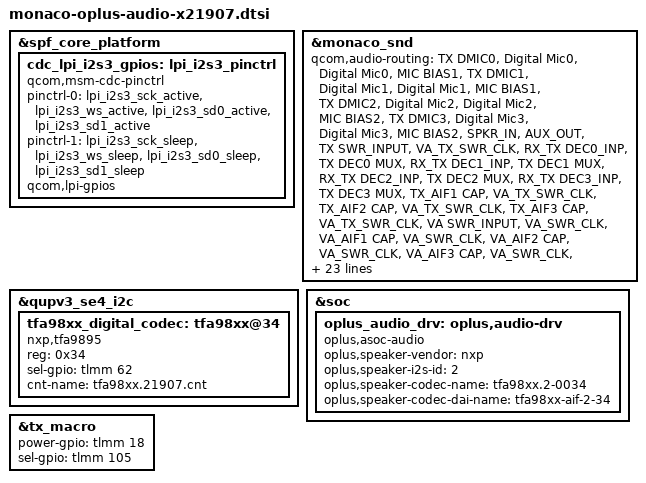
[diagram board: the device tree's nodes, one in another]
//From:

#include <dt-bindings/gpio/gpio.h>

&spf_core_platform {
    cdc_lpi_i2s3_gpios: lpi_i2s3_pinctrl {
        status= "ok";
        compatible = "qcom,msm-cdc-pinctrl";
        pinctrl-names = "aud_active", "aud_sleep";
        pinctrl-0 = <&lpi_i2s3_sck_active &lpi_i2s3_ws_active
                &lpi_i2s3_sd0_active &lpi_i2s3_sd1_active>;
        pinctrl-1 = <&lpi_i2s3_sck_sleep &lpi_i2s3_ws_sleep
                &lpi_i2s3_sd0_sleep &lpi_i2s3_sd1_sleep>;
        #gpio-cells = <0>;
        qcom,lpi-gpios;
    };
};

&monaco_snd {
    qcom,audio-routing =
            "TX DMIC0", "Digital Mic0",
            "Digital Mic0", "MIC BIAS1",
            "TX DMIC1", "Digital Mic1",
            "Digital Mic1", "MIC BIAS1",
            "TX DMIC2", "Digital Mic2",
            "Digital Mic2", "MIC BIAS2",
            "TX DMIC3", "Digital Mic3",
            "Digital Mic3", "MIC BIAS2",
            "SPKR_IN", "AUX_OUT",
            "TX SWR_INPUT", "VA_TX_SWR_CLK",
            "RX_TX DEC0_INP", "TX DEC0 MUX",
            "RX_TX DEC1_INP", "TX DEC1 MUX",
            "RX_TX DEC2_INP", "TX DEC2 MUX",
            "RX_TX DEC3_INP", "TX DEC3 MUX",
            "TX_AIF1 CAP", "VA_TX_SWR_CLK",
            "TX_AIF2 CAP", "VA_TX_SWR_CLK",
            "TX_AIF3 CAP", "VA_TX_SWR_CLK",
            "VA SWR_INPUT", "VA_SWR_CLK",
            "VA_AIF1 CAP", "VA_SWR_CLK",
            "VA_AIF2 CAP", "VA_SWR_CLK",
            "VA_AIF3 CAP", "VA_SWR_CLK",
            "VA DMIC0", "Digital Mic0",
            "VA DMIC1", "Digital Mic1",
            "VA DMIC2", "Digital Mic2",
            "VA DMIC3", "Digital Mic3",
            "VA DMIC0", "VA MIC BIAS1",
            "VA DMIC1", "VA MIC BIAS1",
            "VA DMIC2", "VA MIC BIAS2",
            "VA DMIC3", "VA MIC BIAS2",
            "AMIC1", "Analog Mic1",
            "Analog Mic1","MIC BIAS1",
            "AMIC2", "Analog Mic2",
            "Analog Mic2", "MIC BIAS2",
            "SPKR_IN", "AUX_OUT",
            "TX SWR_INPUT", "VA_TX_SWR_CLK",
            "RX_SWR_TX_PCM_IN0", "RX_MCLK",
            "RX_SWR_TX_PCM_IN1", "RX_MCLK",
            "RX_SWR_TX_PCM_IN0", "ADC1_OUTPUT",
            "RX_SWR_TX_PCM_IN1", "ADC2_OUTPUT",
            "RX_TX DEC0_INP", "TX DEC0 MUX",
            "RX_TX DEC1_INP", "TX DEC1 MUX",
            "RX_TX DEC2_INP", "TX DEC2 MUX",
            "RX_TX DEC3_INP", "TX DEC3 MUX",
            "TX_AIF1 CAP", "VA_TX_SWR_CLK",
            "TX_AIF2 CAP", "VA_TX_SWR_CLK",
            "TX_AIF3 CAP", "VA_TX_SWR_CLK",
            "VA SWR_INPUT", "VA_SWR_CLK",
            "VA_AIF1 CAP", "VA_SWR_CLK",
            "VA_AIF2 CAP", "VA_SWR_CLK",
            "VA_AIF3 CAP", "VA_SWR_CLK";

    qcom,cdc-dmic01-gpios = <&cdc_dmic01_gpios>;
    qcom,tert-mi2s-gpios = <&cdc_lpi_i2s3_gpios>;
};

&qupv3_se4_i2c {
    status = "ok";

    tfa98xx_digital_codec: tfa98xx@34 {
        #sound-dai-cells = <0>;
        compatible = "nxp,tfa9895";
        reg = <0x34>;

        sel-gpio  = <&tlmm 62 GPIO_ACTIVE_HIGH>;

	cnt-name = "tfa98xx.21907.cnt";
        status = "ok";
    };
};

&soc {
	oplus_audio_drv: oplus,audio-drv {
		compatible = "oplus,asoc-audio";
		//for nxp speaker
		oplus,speaker-vendor = "nxp";
		oplus,speaker-i2s-id = <2>;
		oplus,speaker-codec-name = "tfa98xx.2-0034";
		oplus,speaker-codec-dai-name = "tfa98xx-aif-2-34";
	};
};

&tx_macro {
    power-gpio = <&tlmm 18 GPIO_ACTIVE_HIGH>;
    sel-gpio  = <&tlmm 105 GPIO_ACTIVE_HIGH>;
};
